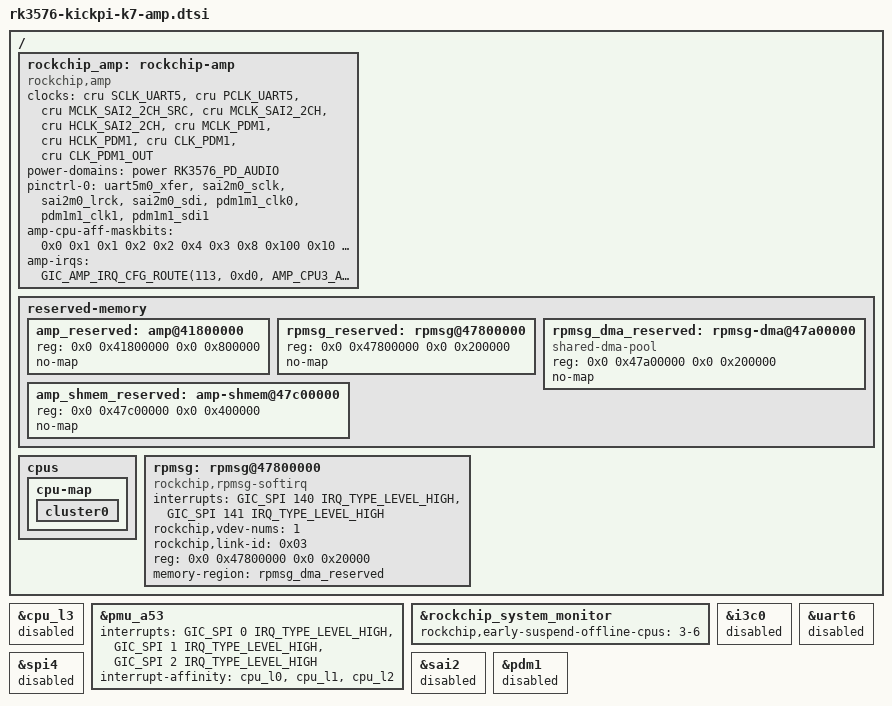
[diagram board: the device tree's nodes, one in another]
// SPDX-License-Identifier: (GPL-2.0+ OR MIT)
/*
 * KickPi K7 (RK3576) AMP: Linux on cpu0-2 (A53) + cpu4-7 (A72),
 * openvela on cpu3 (cpu_l3, MPIDR 0x3, AArch64).
 *
 * Memory map (DRAM base 0x40000000):
 *   0x41800000 +8MB   cpu3 firmware private RAM (no-map)
 *   0x47800000 +2MB   rpmsg vring region (driver uses first 0x20000)
 *   0x47a00000 +2MB   rpmsg buffer pool (shared-dma-pool)
 *   0x47c00000 +4MB   generic shared memory (heartbeat, logs, ...)
 * Kernel load address is moved to 0x42000000 by amp.img linux{} node.
 *
 * IRQ ownership (GIC-400, amp-irqs use absolute INTID = GIC_SPI + 32):
 *   UART5      SPI 81  -> 113  cpu3 console (uart5m0 pins, free on K7 40-pin)
 *   rpmsg tx   SPI 140 -> 172  Linux -> cpu3 kick
 *   rpmsg rx   SPI 141 -> 173  cpu3 -> Linux kick (stays on Linux cores)
 */

#include <dt-bindings/soc/rockchip-amp.h>

/* MPIDR affinity: A53 cluster0 = 0x00-0x03, A72 cluster1 = 0x100-0x103 */
#define CPU_GET_AFFINITY(cpu, cluster)	((cpu) | ((cluster) << 8))
#define AMP_CPU3_AFF			CPU_GET_AFFINITY(3, 0)

/ {
	/* Node name must be "rockchip-amp": rockchip_amp.c looks it up by name */
	rockchip_amp: rockchip-amp {
		compatible = "rockchip,amp";

		/* Keep cpu3-owned peripheral clocks alive against Linux clk
		 * gating: UART5 = openvela console, SAI2 = I2S microphone
		 * front end, PDM1 = PDM microphone front end.  Both mic front
		 * ends are wired up here so switching between them is a
		 * firmware rebuild, not a device-tree change.
		 */
		clocks = <&cru SCLK_UART5>, <&cru PCLK_UART5>,
			 <&cru MCLK_SAI2_2CH_SRC>, <&cru MCLK_SAI2_2CH>,
			 <&cru HCLK_SAI2_2CH>,
			 <&cru MCLK_PDM1>, <&cru HCLK_PDM1>,
			 <&cru CLK_PDM1>, <&cru CLK_PDM1_OUT>;

		/* SAI2 and PDM1 both live in PD_AUDIO.  Linux would gate that
		 * domain off as soon as its own audio is idle, taking the
		 * slave's microphone with it, so hold the domain up here
		 * (rockchip_amp.c does a pm_runtime_resume_and_get() on it).
		 */
		power-domains = <&power RK3576_PD_AUDIO>;

		/* Claim the 40-pin header pins the slave owns:
		 *   UART5 console  GPIO3_D4/D5      (header pins 23/21)
		 *   SAI2 I2S mic   GPIO1_D1/D2/D3   (header pins 18/26/28)
		 *   PDM1 mic       GPIO4_A6/B0/B2   (header pins 7/8/12)
		 * Both PDM clock outputs are claimed so the mic can be wired
		 * to whichever of pin 7 / pin 8 is convenient.
		 */
		pinctrl-names = "default";
		pinctrl-0 = <&uart5m0_xfer>,
			    <&sai2m0_sclk>, <&sai2m0_lrck>, <&sai2m0_sdi>,
			    <&pdm1m1_clk0>, <&pdm1m1_clk1>, <&pdm1m1_sdi1>;

		/* GICv2: MPIDR affinity -> GICD_ITARGETSR cpu mask, all 8 cores */
		amp-cpu-aff-maskbits = /bits/ 64 <
			0x0   0x1  0x1   0x2  0x2   0x4  0x3   0x8
			0x100 0x10 0x101 0x20 0x102 0x40 0x103 0x80>;

		/* SPIs owned by cpu3: routed there and protected from Linux GIC ops */
		amp-irqs = /bits/ 64 <
			GIC_AMP_IRQ_CFG_ROUTE(113, 0xd0, AMP_CPU3_AFF)
			GIC_AMP_IRQ_CFG_ROUTE(172, 0xd0, AMP_CPU3_AFF)>;

		status = "okay";
	};

	reserved-memory {
		#address-cells = <2>;
		#size-cells = <2>;
		ranges;

		amp_reserved: amp@41800000 {
			reg = <0x0 0x41800000 0x0 0x800000>;
			no-map;
		};

		rpmsg_reserved: rpmsg@47800000 {
			reg = <0x0 0x47800000 0x0 0x200000>;
			no-map;
		};

		rpmsg_dma_reserved: rpmsg-dma@47a00000 {
			compatible = "shared-dma-pool";
			reg = <0x0 0x47a00000 0x0 0x200000>;
			no-map;
		};

		amp_shmem_reserved: amp-shmem@47c00000 {
			reg = <0x0 0x47c00000 0x0 0x400000>;
			no-map;
		};
	};

	cpus {
		cpu-map {
			cluster0 {
				/delete-node/ core3;
			};
		};
	};

	/*
	 * Linux <-> cpu3 RPMsg over shared memory, kicked by reserved GIC
	 * SPIs (no mailbox needed). interrupts[0] = tx (Linux -> cpu3,
	 * retriggered, owned by cpu3 via amp-irqs 172); interrupts[1] = rx
	 * (cpu3 -> Linux, cpu3 sets it pending via GICD_ISPENDR).
	 * cpu3 side: openvela rptun/OpenAMP remote, announces "rpmsg-tty"
	 * -> /dev/ttyRPMSG0.
	 */
	rpmsg: rpmsg@47800000 {
		compatible = "rockchip,rpmsg-softirq";
		interrupts = <GIC_SPI 140 IRQ_TYPE_LEVEL_HIGH>,
			     <GIC_SPI 141 IRQ_TYPE_LEVEL_HIGH>;
		rockchip,vdev-nums = <1>;
		rockchip,link-id = <0x03>;	/* master cpu0 / remote cpu3 */
		reg = <0x0 0x47800000 0x0 0x20000>;
		memory-region = <&rpmsg_dma_reserved>;
		status = "okay";
	};
};

/*
 * Hide cpu3 from Linux. NOTE: this kernel's of_get_next_cpu_node() only
 * skips status = "fail" nodes ("disabled" is NOT skipped for cpu nodes).
 */
&cpu_l3 {
	status = "fail";
};

/* cpu_l3 is gone: shrink A53 PMU to the remaining three cores */
&pmu_a53 {
	interrupts = <GIC_SPI 0 IRQ_TYPE_LEVEL_HIGH>,
		     <GIC_SPI 1 IRQ_TYPE_LEVEL_HIGH>,
		     <GIC_SPI 2 IRQ_TYPE_LEVEL_HIGH>;
	interrupt-affinity = <&cpu_l0>, <&cpu_l1>, <&cpu_l2>;
};

/* A72 cores are now logical cpu3-6 (7 CPUs total) */
&rockchip_system_monitor {
	rockchip,early-suspend-offline-cpus = "3-6";
};

/* The SAI2 microphone pins (GPIO1_D1/D2/D3, header pins 18/26/28) are the
 * I3C0 pins on the stock K7 device tree.  I3C0 is unused by this design, so
 * release it to the AMP slave.
 */
&i3c0 {
	status = "disabled";
};

/* The PDM microphone pins are the uart6 (GPIO4_A4/A6, header pins 5/7) and
 * spi4 (GPIO4_B0/B1/B2, header pins 8/10/12) pins on the stock K7 device
 * tree.  A PDM mic needs one clock pin and one data pin out of that set, and
 * pdm1m1_sdi0 — the one group member that would not collide — is not brought
 * out on the K7 header at all.  So both controllers are released to the AMP
 * slave; uart8 (header pins 17/19) remains for Linux.
 */
&uart6 {
	status = "disabled";
};

&spi4 {
	status = "disabled";
};

/* The audio controllers themselves stay disabled on the Linux side: the AMP
 * slave programs them directly.  Linux keeps SAI1/ES8388 (speaker + on-board
 * mic), which is untouched by any of this.
 */
&sai2 {
	status = "disabled";
};

&pdm1 {
	status = "disabled";
};
